VERSION "model fixture 1"

NS_ :

BS_:
BU_: ECU Receiver

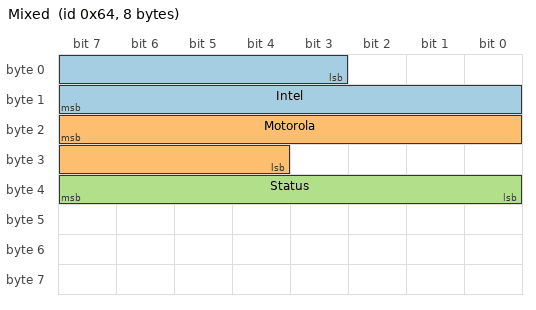
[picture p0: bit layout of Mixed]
BO_ 100 Mixed: 8 ECU
 SG_ Intel : 3|13@1+ (0.5000,-2) [0|4093] "rev per min" Receiver
 SG_ Motorola : 23|12@0- (2.5e-1,+10) [-502|521.75] "deg" Receiver
 SG_ Status : 32|8@1+ (1,0) [0|255] "" Receiver

VAL_ 100 Status 0 "Off" 255 "Not available" ;
BA_ "SPN" SG_ 100 Intel 0;
BA_ "SPN" BO_ 100 61444;

BO_ 2565866513 EEC1_11: 8 ECU
 SG_ Speed : 24|16@1+ (0.125,0) [0|8031.875] "rpm" Receiver

BA_ "J1939Default" BO_ 2565866513 0;
